# APM32F446 register map
File version: 1.0
CPU: CM4 r0p1, little endian, MPU, FPU, 4 interrupt priority bits
Registers are 32-bit, read-write, reset 0x0 unless marked. A register's access mark holds for its fields unless they carry their own. Offsets are from the block's base; [hi:lo] are bit positions; {n}, {i} and the like mark numbered series.

## SYSMC — System Mode Controller
Base 0x4007E000
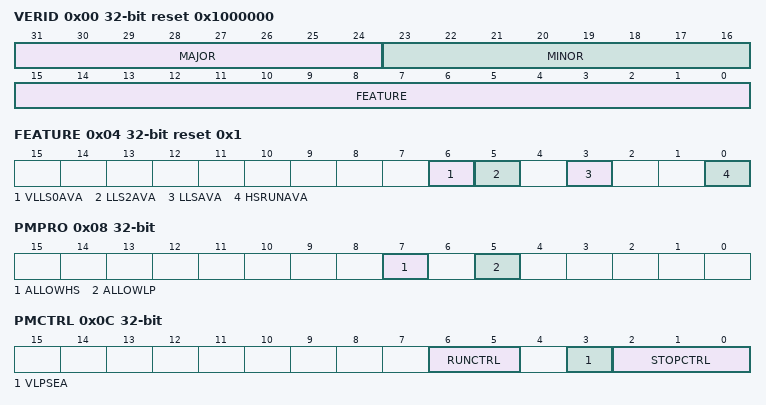
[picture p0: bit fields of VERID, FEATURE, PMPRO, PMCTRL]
0x00 VERID ro reset 0x1000000 — Version ID Register
  [31:24] MAJOR — Major Version Number
  [23:16] MINOR — Minor Version Number
  [15:0] FEATURE — Feature Number
    0=Standard features implemented
0x04 FEATURE ro reset 0x1
  [all] fields
    0=The feature is not available; 1=The feature is available
  [6] VLLS0AVA — VLLS0 Feature Available
  [5] LLS2AVA — LLS2 Feature Available
  [3] LLSAVA — LLS Feature Available
  [0] HSRUNAVA — HSRUN Feature Available
0x08 PMPRO — Power Mode Protection register
  [7] ALLOWHS — Allow MCU Enter High-Speed Run Mode
    0=HSRUN is not allowed; 1=HSRUN is allowed
  [5] ALLOWLP — Allow MCU Enter Very Low Power Mode
    0=VLPR and VLPS are not allowed; 1=VLPR and VLPS are allowed
0x0C PMCTRL — Power Mode Control register
  [6:5] RUNCTRL — Run Mode Control
    0=Normal Run mode (RUN); 2=Very-Low-Power Run mode (VLPR); 3=High Speed Run mode (HSRUN)
  [3] VLPSEA ro — Very Low Power Stop Mode Entry Aborted
    0=The previous stop mode entry was successful; 1=The previous stop mode entry was aborted
  [2:0] STOPCTRL — Stop Mode Control
    0=Normal Stop (STOP); 2=Very-Low-Power Stop (VLPS); 6=Reseved
0x10 STOPOSEL reset 0x3 — Stop Operation Select Register
  [7:6] STOPOSEL — Stop Operation Select
    1=STOP1 - Stop with both system and bus clocks disabled; 2=STOP2 - Stop with system clock disabled and bus clock enabled
0x14 PMSTS ro reset 0x1 — Power Mode Status register
  [7:0] PMSTS — Power Mode Status

## GPIOA — General Purpose Input/Output
Base 0x400FF000
Same registers: GPIOB 0x400FF040, GPIOC 0x400FF080, GPIOD 0x400FF0C0, GPIOE 0x400FF100
0x00 PLLO — Port Logic Level Output Register
  [31:0] PLLO — Port Logic Level Output
0x04 PLLOS wo — Port Logic Level Output Set Register
  [31:0] PLLOS — Port Logic Level Output Set
0x08 PLLOC wo — Port Logic Level Output Clear Register
  [31:0] PLLOC — Port Logic Level Output Clear
0x0C PLLOT wo — Port Logic Level Output Toggle Register
  [31:0] PLLOT — Port Logic Level Output Toggle
0x10 PLLI ro — Port Logic Level Input Register
  [31:0] PLLI — Port Logic Level Input
0x14 PLLTDS — Port Logic Level Transfer Direction Select Register
  [31:0] PLLTDS — Port Logic Level Transfer Direction Select
0x18 PLLID — Port Logic Level Input Disable Register
  [31:0] PLLID — Port Logic Level Input Disable

## APM32_SysTick — System timer
Base 0xE000E010
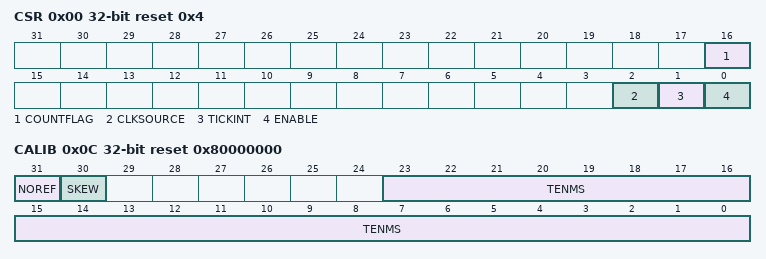
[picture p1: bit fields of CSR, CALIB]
0x00 CSR reset 0x4 — SysTick Control and Status Register
  [16] COUNTFLAG — Returns 1 if timer counted to 0 since last time this was read
  [2] CLKSOURCE — Indicates the clock source
    0=external clock; 1=processor clock
  [1] TICKINT — Enables SysTick exception request
    0=counting down to 0 does not assert the SysTick exception request; 1=counting down to 0 asserts the SysTick exception request
  [0] ENABLE — Enables the counter
    0=counter disabled; 1=counter enabled
0x04 RVR — SysTick Reload Value Register
  [23:0] RELOAD — Value to load into the SysTick Current Value Register when the counter reaches 0
0x08 CVR — SysTick Current Value Register
  [23:0] CURRENT — Current value at the time the register is accessed
0x0C CALIB ro reset 0x80000000 — SysTick Calibration Value Register
  [31] NOREF — Indicates whether the device provides a reference clock to the processor
    0=The reference clock is provided; 1=The reference clock is not provided
  [30] SKEW — Indicates whether the TENMS value is exact
    0=TENMS value is exact; 1=TENMS value is inexact, or not given
  [23:0] TENMS — Reload value to use for 10ms timing

## APM32_NVIC — Nested Vectored Interrupt Controller
Base 0xE000E100
{0x0+4i} NVICISER{i} (i=0..7) — Interrupt Set Enable Register n
  [31:0] SETENA — Interrupt set enable bits
{0x80+4i} NVICICER{i} (i=0..7) — Interrupt Clear Enable Register n
  [31:0] CLRENA — Interrupt clear-enable bits
{0x100+4i} NVICISPR{i} (i=0..7) — Interrupt Set Pending Register n
  [31:0] SETPEND — Interrupt set-pending bits
{0x180+4i} NVICICPR{i} (i=0..7) — Interrupt Clear Pending Register n
  [31:0] CLRPEND — Interrupt clear-pending bits
{0x200+4i} NVICIABR{i} (i=0..7) — Interrupt Active bit Register n
  [31:0] ACTIVE — Interrupt active flags
{0x300+i} NVICIP{i} 8-bit (i=0..239) — Interrupt Priority Register n
  [7:0] PRI{i} — Priority of interrupt {i}
0xE00 NVICSTIR wo — Software Trigger Interrupt Register
  [8:0] INTID — Interrupt ID of the interrupt to trigger, in the range 0-239. For example, a value of 0x03 specifies interrupt IRQ3.

## LMC — Local Memory Controller
Base 0xE0082000
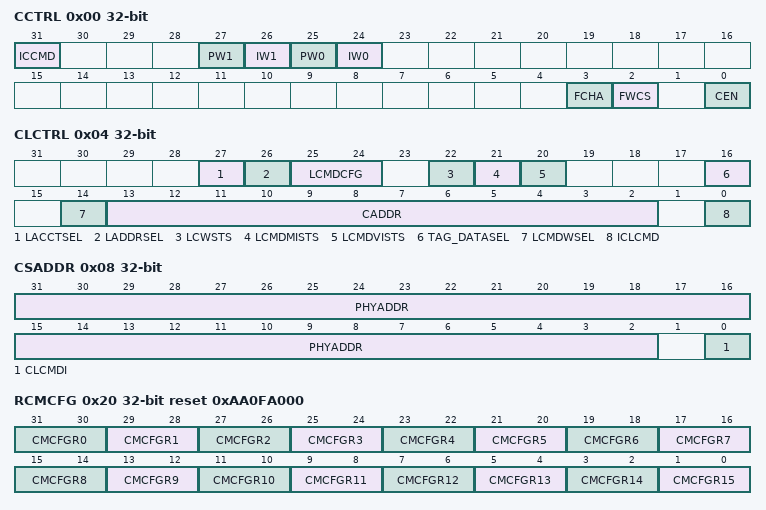
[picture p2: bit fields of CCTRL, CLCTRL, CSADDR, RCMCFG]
0x00 CCTRL — Cache Control Register
  [31] ICCMD — Initiate Cache Command
    0=Write: no effect. Read: no cache command active.; 1=Write: initiate command indicated by bits 27-24. Read: cache command active.
  [27] PW1 — Push Way 1
    0=No operation; 1=When setting the GO bit, push all modified lines in way 1
  [26] IW1 — Invalidate Way 1
    0=No operation; 1=When setting the GO bit, invalidate all lines in way 1
  [25] PW0 — Push Way 0
    0=No operation; 1=When setting the GO bit, push all modified lines in way 0
  [24] IW0 — Invalidate Way 0
    0=No operation; 1=When setting the GO bit, invalidate all lines in way 0
  [3] FCHA — Force Cache Hit Allocation
  [2] FWCS — Force Write to Cacheable Space
  [0] CEN — Cache Enable
    0=Cache disabled; 1=Cache enabled
0x04 CLCTRL — Cache Line Control Register
  [27] LACCTSEL — Line Access Type Select
    0=Read; 1=Write
  [26] LADDRSEL — Line Address Select
    0=Cache address; 1=Physical address
  [25:24] LCMDCFG — Line Command Configure
    0=Search and read or write; 1=Invalidate; 2=Push; 3=Clear
  [22] LCWSTS — Line Command Way Statue
  [21] LCMDMISTS — Line Command Modified Bit Initial State
  [20] LCMDVISTS — Line Command Valid Bit Initial State
  [16] TAG_DATASEL — Tag/Data Select
    0=Data; 1=Tag
  [14] LCMDWSEL — Line Command Way Select
    0=Way 0; 1=Way 1
  [13:2] CADDR — Cache Address
  [0] ICLCMD — Initiate Cache Line Command
    0=Write: no effect. Read: no line command active.; 1=Write: initiate line command indicated by bits 27-24. Read: line command active.
0x08 CSADDR — Cache Search Address Register
  [31:2] PHYADDR — Physical Address
  [0] CLCMDI — Cache Line Command Initiate
    0=Write: no effect. Read: no line command active.; 1=Write: initiate line command indicated by bits CLCR[27:24]. Read: line command active.
0x0C CDATA — Cache Data Register
  [31:0] CDATA — Cache Data
0x20 RCMCFG reset 0xAA0FA000 — Region Cache Mode Configure Register
  [1:0] CMCFGR{x} (x=15,14,13,12,11,10,9,8,7,6,5,4,3,2,1,0; step 2) — Region 0-15 mode
    0=Non-cacheable; 1=Non-cacheable; 2=Write-through; 3=Write-back
